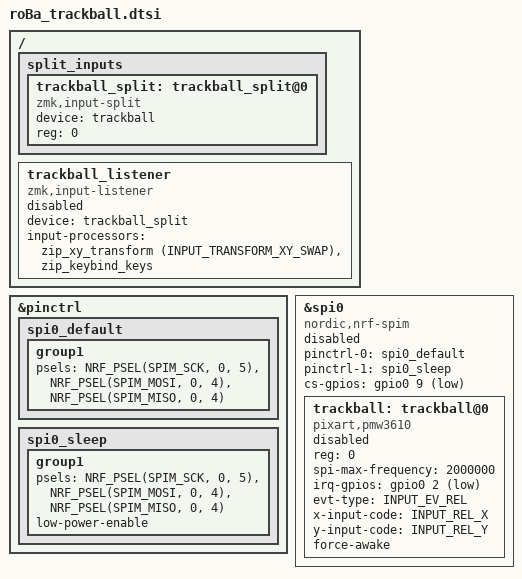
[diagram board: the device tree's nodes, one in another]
#include <zephyr/dt-bindings/input/input-event-codes.h>
#include <input/processors/zmk-input-processor-keybind.dtsi>

&pinctrl {
    spi0_default: spi0_default {
        group1 {
            psels = <NRF_PSEL(SPIM_SCK, 0, 5)>,
                <NRF_PSEL(SPIM_MOSI, 0, 4)>,
                <NRF_PSEL(SPIM_MISO, 0, 4)>;
        };
    };

    spi0_sleep: spi0_sleep {
        group1 {
            psels = <NRF_PSEL(SPIM_SCK, 0, 5)>,
                <NRF_PSEL(SPIM_MOSI, 0, 4)>,
                <NRF_PSEL(SPIM_MISO, 0, 4)>;
            low-power-enable;
        };
    };
};
&spi0 {
    status = "disabled";
    compatible = "nordic,nrf-spim";
    pinctrl-0 = <&spi0_default>;
    pinctrl-1 = <&spi0_sleep>;
    pinctrl-names = "default", "sleep";
    cs-gpios = <&gpio0 9 GPIO_ACTIVE_LOW>;

    trackball: trackball@0 {
        status = "disabled";
        compatible = "pixart,pmw3610";
        reg = <0>;
        spi-max-frequency = <2000000>;
        irq-gpios = <&gpio0 2 (GPIO_ACTIVE_LOW | GPIO_PULL_UP)>;
        evt-type = <INPUT_EV_REL>;
	    x-input-code = <INPUT_REL_X>;
	    y-input-code = <INPUT_REL_Y>;
        force-awake;
    };
};



/ {
    split_inputs {
        #address-cells = <1>;
        #size-cells = <0>;

        trackball_split: trackball_split@0 {
            device = <&trackball>;
            compatible = "zmk,input-split";
            reg = <0>;
        };
    };

    trackball_listener: trackball_listener {
    compatible = "zmk,input-listener";
    status = "disabled";
    device = <&trackball_split>;
    input-processors = <&zip_xy_transform (INPUT_TRANSFORM_XY_SWAP)>,
                   <&zip_keybind_keys>;

    };
  };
